# ADI_4_AUX register map
Vendor: Texas Instruments
Peripheral module from a debugger description file (folder CC2652).
Registers are 8-bit, read-write, reset 0x0 unless marked. A register's access mark holds for its fields unless they carry their own. Offsets are as the file gives them; lines under a group give offsets from that group; [hi:lo] are bit positions; {n}, {i} and the like mark numbered series; 'fields as' and 'values as' point back to an identical list; <NAME> marks a mode.

## AUX_ADI4 — Configuration registers controlling analog peripherals of AUX. Registers Fields should be considered static unless otherwise noted (as dynamic)
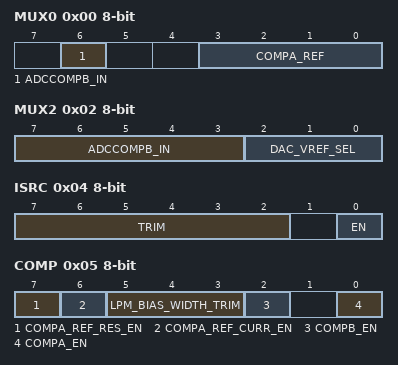
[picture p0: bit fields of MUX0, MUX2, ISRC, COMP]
0x00 MUX0 — Internal. Only to be used through TI provided API.
  [6] ADCCOMPB_IN — Internal. Only to be used through TI provided API.
    1=VDDR_1P8V (Internal. Only to be used through TI provided API.); 0=NC (Internal. Only to be used through TI provided API.)
  [3:0] COMPA_REF — Internal. Only to be used through TI provided API.
    8=ADCVREFP (Internal. Only to be used through TI provided API.); 4=VDDS (Internal. Only to be used through TI provided API.); 2=VSS (Internal. Only to be used through TI provided API.); 1=DCOUPL (Internal. Only to be used through TI provided API.); 0=NC (Internal. Only to be used through TI provided API.)
0x01 MUX1 — Internal. Only to be used through TI provided API.
  [7:0] COMPA_IN
    128=AUXIO19 (Internal. Only to be used through TI provided API.); 64=AUXIO20 (Internal. Only to be used through TI provided API.); 32=AUXIO21 (Internal. Only to be used through TI provided API.); 16=AUXIO22 (Internal. Only to be used through TI provided API.); 8=AUXIO23 (Internal. Only to be used through TI provided API.); 4=AUXIO24 (Internal. Only to be used through TI provided API.); 2=AUXIO25 (Internal. Only to be used through TI provided API.); 1=AUXIO26 (Internal. Only to be used through TI provided API.); 0=NC (Internal. Only to be used through TI provided API.)
0x02 MUX2 — Internal. Only to be used through TI provided API.
  [7:3] ADCCOMPB_IN — Internal. Only to be used through TI provided API.
    16=VDDS (Internal. Only to be used through TI provided API.); 8=VSS (Internal. Only to be used through TI provided API.); 4=DCOUPL (Internal. Only to be used through TI provided API.); 2=ATEST1 (Internal. Only to be used through TI provided API.); 1=ATEST0 (Internal. Only to be used through TI provided API.); 0=NC (Internal. Only to be used through TI provided API.)
  [2:0] DAC_VREF_SEL — Internal. Only to be used through TI provided API.
    4=VDDS (Internal. Only to be used through TI provided API.); 2=ADCREF (Internal. Only to be used through TI provided API.); 1=DCOUPL (Internal. Only to be used through TI provided API.); 0=NC (Internal. Only to be used through TI provided API.)
0x03 MUX3 — Internal. Only to be used through TI provided API.
  [7:0] ADCCOMPB_IN
    values as MUX1.COMPA_IN
0x04 ISRC — Current Source Strength and trim control for current source. Only to be used through TI provided API.
  [7:2] TRIM — Adjust current from current source. Output currents may be combined to get desired total current.
    32=11P75U (11.75 uA); 16=4P5U (4.5 uA); 8=2P0U (2.0 uA); 4=1P0U (1.0 uA); 2=0P5U (0.5 uA); 1=0P25U (0.25 uA); 0=NC (No current connected)
  [0] EN — Current source enable
0x05 COMP — Comparator Control COMPA and COMPB comparators. Only to be used through TI provided API.
  [7] COMPA_REF_RES_EN — Enables 400kohm resistance from COMPA reference node to ground. Used with COMPA_REF_CURR_EN to generate voltage reference for cap-sense.
  [6] COMPA_REF_CURR_EN — Enables 2uA IPTAT current from ISRC to COMPA reference node. Requires ISRC.EN = 1. Used with COMPA_REF_RES_EN to generate voltage reference for cap-sense.
  [5:3] LPM_BIAS_WIDTH_TRIM — Internal. Only to be used through TI provided API.
  [2] COMPB_EN — COMPB enable
  [0] COMPA_EN — COMPA enable
0x07 MUX4 — Internal. Only to be used through TI provided API.
  [7:0] COMPA_REF
    values as MUX1.COMPA_IN
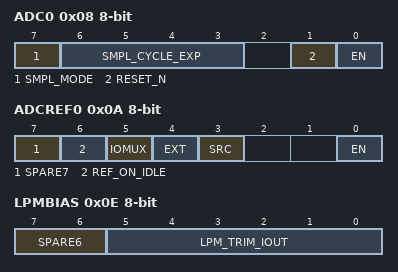
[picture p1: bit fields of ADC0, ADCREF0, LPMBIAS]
0x08 ADC0 — ADC Control 0 ADC Sample Control. Only to be used through TI provided API.
  [7] SMPL_MODE — ADC Sampling mode: 0: Synchronous mode 1: Asynchronous mode The ADC does a sample-and-hold before conversion. In synchronous mode the sampling starts when the ADC clock detects a rising edge on the trigger signal. Jitter/uncertainty will be inferred in the detection if the trigger signal originates from a domain that is asynchronous to the ADC clock. SMPL_CYCLE_EXP determines the the duration of sampling. Conversion starts immediately after sampling ends. In asynchronous mode the sampling is continuous when enabled. Sampling ends and conversion starts immediately with the rising edge of the trigger signal. Sampling restarts when the conversion has finished. Asynchronous mode is useful when it is important to avoid jitter in the sampling instant of an externally driven signal
  [6:3] SMPL_CYCLE_EXP — Controls the sampling duration before conversion when the ADC is operated in synchronous mode (SMPL_MODE = 0). The setting has no effect in asynchronous mode. The sampling duration is given as 2^(SMPL_CYCLE_EXP + 1) / 6 us.
    15=10P9_MS (65536x 6 MHz clock periods = 10.9ms); 14=5P46_MS (32768x 6 MHz clock periods = 5.46ms); 13=2P73_MS (16384x 6 MHz clock periods = 2.73ms); 12=1P37_MS (8192x 6 MHz clock periods = 1.37ms); 11=682_US (4096x 6 MHz clock periods = 682us); 10=341_US (2048x 6 MHz clock periods = 341us); 9=170_US (1024x 6 MHz clock periods = 170us); 8=85P3_US (512x 6 MHz clock periods = 85.3us); 7=42P6_US (256x 6 MHz clock periods = 42.6us); 6=21P3_US (128x 6 MHz clock periods = 21.3us); 5=10P6_US (64x 6 MHz clock periods = 10.6us); 4=5P3_US (32x 6 MHz clock periods = 5.3us); 3=2P7_US (16x 6 MHz clock periods = 2.7us)
  [1] RESET_N — Reset ADC digital subchip, active low. ADC must be reset every time it is reconfigured. 0: Reset 1: Normal operation
  [0] EN — ADC Enable 0: Disable 1: Enable
0x09 ADC1 — ADC Control 1 ADC Comparator Control. Only to be used through TI provided API.
  [0] SCALE_DIS — Internal. Only to be used through TI provided API.
0x0A ADCREF0 — ADC Reference 0 Control reference used by the ADC. Only to be used through TI provided API.
  [7] SPARE7 — Software should not rely on the value of a reserved. Writing any other value than the reset value may result in undefined behavior.
  [6] REF_ON_IDLE — Enable ADCREF in IDLE state. 0: Disabled in IDLE state 1: Enabled in IDLE state Keep ADCREF enabled when ADC0.SMPL_MODE = 0. Recommendation: Enable ADCREF always when ADC0.SMPL_CYCLE_EXP is less than 0x6 (21.3us sampling time).
  [5] IOMUX — Internal. Only to be used through TI provided API.
  [4] EXT — Internal. Only to be used through TI provided API.
  [3] SRC — ADC reference source: 0: Fixed reference = 4.3V 1: Relative reference = VDDS
  [0] EN — ADC reference module enable: 0: ADC reference module powered down 1: ADC reference module enabled
0x0B ADCREF1 — ADC Reference 1 Control reference used by the ADC. Only to be used through TI provided API.
  [5:0] VTRIM — Trim output voltage of ADC fixed reference (64 steps, 2's complement). Applies only for ADCREF0.SRC = 0. Examples: 0x00 - nominal voltage 1.43V 0x01 - nominal + 0.4% 1.435V 0x3F - nominal - 0.4% 1.425V 0x1F - maximum voltage 1.6V 0x20 - minimum voltage 1.3V
0x0E LPMBIAS — Internal. Only to be used through TI provided API.
  [7:6] SPARE6 — Internal. Only to be used through TI provided API.
  [5:0] LPM_TRIM_IOUT — Internal. Only to be used through TI provided API.
0x0F STAT ro — Software should not rely on the value of a reserved. Writing any other value than the reset value may result in undefined behavior.
  [7:0] SPARE0
